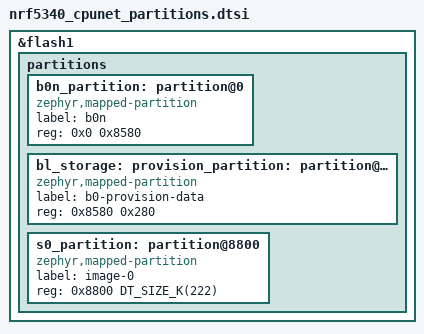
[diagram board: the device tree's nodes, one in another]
/*
 * Copyright (c) 2026 Nordic Semiconductor ASA
 *
 * SPDX-License-Identifier: LicenseRef-Nordic-5-Clause
 */

/delete-node/ &boot_partition;
/delete-node/ &slot0_partition;
/delete-node/ &slot1_partition;
/delete-node/ &storage_partition;

&flash1 {
	partitions {
		b0n_partition: partition@0 {
			compatible = "zephyr,mapped-partition";
			label = "b0n";
			reg = <0x0 0x8580>;
		};

		bl_storage: provision_partition: partition@8580 {
			compatible = "zephyr,mapped-partition";
			label = "b0-provision-data";
			reg = <0x8580 0x280>;
		};

		s0_partition: partition@8800 {
			compatible = "zephyr,mapped-partition";
			label = "image-0";
			reg = <0x8800 DT_SIZE_K(222)>;
		};
	};
};
